AUTOSAR XML (schema 00051)
package /adcm/AdaptiveApplicationSwComponentTypes
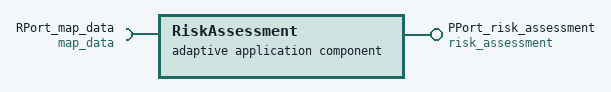
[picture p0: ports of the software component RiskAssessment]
  adaptive application sw component type RiskAssessment
    provide port PPort_risk_assessment: provided-interface=risk_assessment
    require port RPort_map_data: required-interface=map_data
package /adcm/Executables
  executable RiskAssessment: category=APPLICATION_LEVEL, minimum-timer-granularity=1000
    root sw component prototype RiskAssessment: application-type=RiskAssessment
